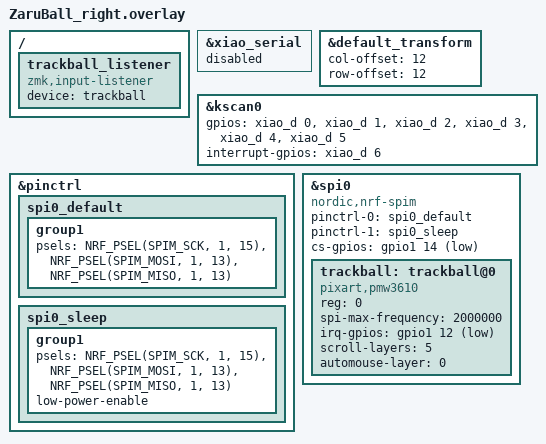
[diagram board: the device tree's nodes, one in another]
#include "ZaruBall.dtsi"
//#include <dt-bindings/zmk/input_transform.h>

&xiao_serial { status = "disabled"; };

// matrix transformでのピン数オフセット
&default_transform { // Offset of 7 because the left side has 2 columns
    col-offset = <12>;
    row-offset = <12>;
};

&kscan0 {
    gpios
        = <&xiao_d 0 GPIO_ACTIVE_HIGH>//M1
        , <&xiao_d 1 GPIO_ACTIVE_HIGH>//M2
        , <&xiao_d 2 GPIO_ACTIVE_HIGH>//M3
        , <&xiao_d 3 GPIO_ACTIVE_HIGH>//M4
        , <&xiao_d 4 GPIO_ACTIVE_HIGH>//M5
        , <&xiao_d 5 GPIO_ACTIVE_HIGH>//M6
        ;
    interrupt-gpios = <&xiao_d 6 (GPIO_ACTIVE_HIGH | GPIO_PULL_DOWN)>;//IGPIO
};

// pmw-3610-driverを動かすコード（古いブランチ:pointers-move-scroll）----------------------------------
&pinctrl {
    spi0_default: spi0_default {
        group1 {
            psels = <NRF_PSEL(SPIM_SCK, 1, 15)>, // SCLK
                <NRF_PSEL(SPIM_MOSI, 1, 13)>, // SDIO
                <NRF_PSEL(SPIM_MISO, 1, 13)>; // SDIO
        };
    };

    spi0_sleep: spi0_sleep {
        group1 {
            psels = <NRF_PSEL(SPIM_SCK, 1, 15)>,
                <NRF_PSEL(SPIM_MOSI, 1, 13)>,
                <NRF_PSEL(SPIM_MISO, 1, 13)>;
            low-power-enable;
        };
    };
};

&spi0 {
    status = "okay";
    compatible = "nordic,nrf-spim";
    pinctrl-0 = <&spi0_default>;
    pinctrl-1 = <&spi0_sleep>;
    pinctrl-names = "default", "sleep";
    cs-gpios = <&gpio1 14 GPIO_ACTIVE_LOW>; // CS

    trackball: trackball@0 {
        status = "okay";
        compatible = "pixart,pmw3610";
        reg = <0>;
        spi-max-frequency = <2000000>;
        irq-gpios = <&gpio1 12 (GPIO_ACTIVE_LOW | GPIO_PULL_UP)>; // MOTION

        /*   optional features   */
        // snipe-layers = <1 2>;
        scroll-layers = <5>;
        /* Disable automouse layer until pmw3610 driver is updated for new API */
        automouse-layer = <0>;
    };
};

/ {
  trackball_listener {
    compatible = "zmk,input-listener";
    device = <&trackball>;
  };
};
